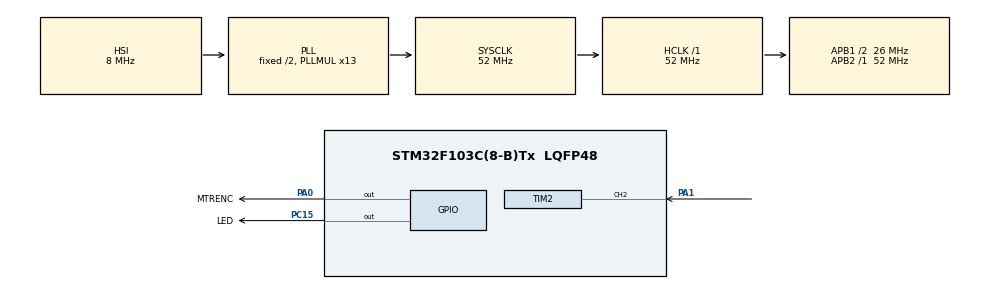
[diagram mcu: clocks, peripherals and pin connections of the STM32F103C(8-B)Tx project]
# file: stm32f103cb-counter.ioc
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Mcu.Family=STM32F1
Mcu.Name=STM32F103C(8-B)Tx
Mcu.Package=LQFP48
NVIC.PriorityGroup=NVIC_PRIORITYGROUP_4
NVIC.TIM1_BRK_IRQn=true\:0\:0\:false\:false\:true\:true\:true
NVIC.TIM1_CC_IRQn=true\:0\:0\:false\:false\:true\:true\:true
NVIC.TIM1_TRG_COM_IRQn=true\:0\:0\:false\:false\:true\:true\:true
NVIC.TIM1_UP_IRQn=true\:0\:0\:false\:false\:true\:true\:true
PA0-WKUP.GPIO_Label=MTRENC
PA0-WKUP.Signal=GPIO_Output
PA1.Signal=S_TIM2_CH2
PA13.Mode=Serial_Wire
PA13.Signal=SYS_JTMS-SWDIO
PA14.Mode=Serial_Wire
PA14.Signal=SYS_JTCK-SWCLK
PC15-OSC32_OUT.GPIO_Label=LED
PC15-OSC32_OUT.Signal=GPIO_Output
ProjectManager.HeapSize=0x200
ProjectManager.StackSize=0x400
ProjectManager.TargetToolchain=STM32CubeIDE
RCC.AHBFreq_Value=52000000
RCC.APB1CLKDivider=RCC_HCLK_DIV2
RCC.APB1Freq_Value=26000000
RCC.APB1TimFreq_Value=52000000
RCC.APB2Freq_Value=52000000
RCC.APB2TimFreq_Value=52000000
RCC.HCLKFreq_Value=52000000
RCC.PLLMUL=RCC_PLL_MUL13
RCC.SYSCLKFreq_VALUE=52000000
RCC.SYSCLKSource=RCC_SYSCLKSOURCE_PLLCLK
RCC.USBFreq_Value=52000000
SH.S_TIM2_CH2.0=TIM2_CH2,TriggerSource_TI2FP2
TIM1.AutoReloadPreload=TIM_AUTORELOAD_PRELOAD_ENABLE
TIM1.Period=10000
TIM1.Prescaler=52
VP_TIM1_VS_ClockSourceINT.Mode=Internal
VP_TIM2_VS_ControllerModeClock.Mode=Clock Mode
board=custom

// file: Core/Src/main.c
/* USER CODE BEGIN Header */
/**
  ******************************************************************************
  * @file           : main.c
  * @brief          : Main program body
  ******************************************************************************
  * @attention
  *
  * <h2><center>&copy; Copyright (c) 2020 STMicroelectronics.
  * All rights reserved.</center></h2>
  *
  * This software component is licensed by ST under BSD 3-Clause license,
  * the "License"; You may not use this file except in compliance with the
  * License. You may obtain a copy of the License at:
  *                        opensource.org/licenses/BSD-3-Clause
  *
  ******************************************************************************
  */
/* USER CODE END Header */
#include "main.h"

TIM_HandleTypeDef htim1;
TIM_HandleTypeDef htim2;

/* USER CODE BEGIN PV */
int tim1Cnt=0;
uint32_t rpmValue=0;
/* USER CODE END PV */

void SystemClock_Config(void);
static void MX_GPIO_Init(void);
static void MX_TIM1_Init(void);
static void MX_TIM2_Init(void);

int main(void)
{

  /* MCU Configuration--------------------------------------------------------*/

  /* Reset of all peripherals, Initializes the Flash interface and the Systick. */
  HAL_Init();

  /* Configure the system clock */
  SystemClock_Config();

  /* Initialize all configured peripherals */
  MX_GPIO_Init();
  MX_TIM1_Init();
  MX_TIM2_Init();
  /* USER CODE BEGIN 2 */
  HAL_GPIO_WritePin(MTRENC_GPIO_Port, MTRENC_Pin, GPIO_PIN_RESET);

  /* USER CODE END 2 */

  /* Infinite loop */
  /* USER CODE BEGIN WHILE */
  while (HAL_TIM_Base_Start_IT(&htim1)!=HAL_OK);
  while (HAL_TIM_Base_Start(&htim2)!=HAL_OK);
  while (1)
  {
    /* USER CODE END WHILE */

  }
}

void SystemClock_Config(void)
{
  RCC_OscInitTypeDef RCC_OscInitStruct = {0};
  RCC_ClkInitTypeDef RCC_ClkInitStruct = {0};

  /** Initializes the RCC Oscillators according to the specified parameters
  * in the RCC_OscInitTypeDef structure.
  */
  RCC_OscInitStruct.OscillatorType = RCC_OSCILLATORTYPE_HSI;
  RCC_OscInitStruct.HSIState = RCC_HSI_ON;
  RCC_OscInitStruct.HSICalibrationValue = RCC_HSICALIBRATION_DEFAULT;
  RCC_OscInitStruct.PLL.PLLState = RCC_PLL_ON;
  RCC_OscInitStruct.PLL.PLLSource = RCC_PLLSOURCE_HSI_DIV2;
  RCC_OscInitStruct.PLL.PLLMUL = RCC_PLL_MUL13;
  if (HAL_RCC_OscConfig(&RCC_OscInitStruct) != HAL_OK)
  {
    Error_Handler();
  }
  /** Initializes the CPU, AHB and APB buses clocks
  */
  RCC_ClkInitStruct.ClockType = RCC_CLOCKTYPE_HCLK|RCC_CLOCKTYPE_SYSCLK
                              |RCC_CLOCKTYPE_PCLK1|RCC_CLOCKTYPE_PCLK2;
  RCC_ClkInitStruct.SYSCLKSource = RCC_SYSCLKSOURCE_PLLCLK;
  RCC_ClkInitStruct.AHBCLKDivider = RCC_SYSCLK_DIV1;
  RCC_ClkInitStruct.APB1CLKDivider = RCC_HCLK_DIV2;
  RCC_ClkInitStruct.APB2CLKDivider = RCC_HCLK_DIV1;

  if (HAL_RCC_ClockConfig(&RCC_ClkInitStruct, FLASH_LATENCY_2) != HAL_OK)
  {
    Error_Handler();
  }
}

static void MX_TIM1_Init(void)
{

  TIM_ClockConfigTypeDef sClockSourceConfig = {0};
  TIM_MasterConfigTypeDef sMasterConfig = {0};

  htim1.Instance = TIM1;
  htim1.Init.Prescaler = 52;
  htim1.Init.CounterMode = TIM_COUNTERMODE_UP;
  htim1.Init.Period = 10000;
  htim1.Init.ClockDivision = TIM_CLOCKDIVISION_DIV1;
  htim1.Init.RepetitionCounter = 0;
  htim1.Init.AutoReloadPreload = TIM_AUTORELOAD_PRELOAD_ENABLE;
  if (HAL_TIM_Base_Init(&htim1) != HAL_OK)
  {
    Error_Handler();
  }
  sClockSourceConfig.ClockSource = TIM_CLOCKSOURCE_INTERNAL;
  if (HAL_TIM_ConfigClockSource(&htim1, &sClockSourceConfig) != HAL_OK)
  {
    Error_Handler();
  }
  sMasterConfig.MasterOutputTrigger = TIM_TRGO_RESET;
  sMasterConfig.MasterSlaveMode = TIM_MASTERSLAVEMODE_DISABLE;
  if (HAL_TIMEx_MasterConfigSynchronization(&htim1, &sMasterConfig) != HAL_OK)
  {
    Error_Handler();
  }

}

static void MX_TIM2_Init(void)
{

  TIM_SlaveConfigTypeDef sSlaveConfig = {0};
  TIM_MasterConfigTypeDef sMasterConfig = {0};

  htim2.Instance = TIM2;
  htim2.Init.Prescaler = 0;
  htim2.Init.CounterMode = TIM_COUNTERMODE_UP;
  htim2.Init.Period = 65535;
  htim2.Init.ClockDivision = TIM_CLOCKDIVISION_DIV1;
  htim2.Init.AutoReloadPreload = TIM_AUTORELOAD_PRELOAD_DISABLE;
  if (HAL_TIM_Base_Init(&htim2) != HAL_OK)
  {
    Error_Handler();
  }
  sSlaveConfig.SlaveMode = TIM_SLAVEMODE_EXTERNAL1;
  sSlaveConfig.InputTrigger = TIM_TS_TI2FP2;
  sSlaveConfig.TriggerPolarity = TIM_TRIGGERPOLARITY_RISING;
  sSlaveConfig.TriggerFilter = 0;
  if (HAL_TIM_SlaveConfigSynchro(&htim2, &sSlaveConfig) != HAL_OK)
  {
    Error_Handler();
  }
  sMasterConfig.MasterOutputTrigger = TIM_TRGO_RESET;
  sMasterConfig.MasterSlaveMode = TIM_MASTERSLAVEMODE_DISABLE;
  if (HAL_TIMEx_MasterConfigSynchronization(&htim2, &sMasterConfig) != HAL_OK)
  {
    Error_Handler();
  }

}

static void MX_GPIO_Init(void)
{
  GPIO_InitTypeDef GPIO_InitStruct = {0};

  /* GPIO Ports Clock Enable */
  __HAL_RCC_GPIOC_CLK_ENABLE();
  __HAL_RCC_GPIOA_CLK_ENABLE();

  /*Configure GPIO pin Output Level */
  HAL_GPIO_WritePin(LED_GPIO_Port, LED_Pin, GPIO_PIN_RESET);

  /*Configure GPIO pin Output Level */
  HAL_GPIO_WritePin(MTRENC_GPIO_Port, MTRENC_Pin, GPIO_PIN_RESET);

  /*Configure GPIO pin : LED_Pin */
  GPIO_InitStruct.Pin = LED_Pin;
  GPIO_InitStruct.Mode = GPIO_MODE_OUTPUT_PP;
  GPIO_InitStruct.Pull = GPIO_NOPULL;
  GPIO_InitStruct.Speed = GPIO_SPEED_FREQ_LOW;
  HAL_GPIO_Init(LED_GPIO_Port, &GPIO_InitStruct);

  /*Configure GPIO pin : MTRENC_Pin */
  GPIO_InitStruct.Pin = MTRENC_Pin;
  GPIO_InitStruct.Mode = GPIO_MODE_OUTPUT_PP;
  GPIO_InitStruct.Pull = GPIO_NOPULL;
  GPIO_InitStruct.Speed = GPIO_SPEED_FREQ_LOW;
  HAL_GPIO_Init(MTRENC_GPIO_Port, &GPIO_InitStruct);

}

/* USER CODE BEGIN 4 */
void HAL_TIM_PeriodElapsedCallback(TIM_HandleTypeDef *htim)
{

	uint32_t count;
	__NOP();
   if (htim->Instance==TIM1)
	  {
	   if (tim1Cnt==100)
	   {
		   count = __HAL_TIM_GET_COUNTER(&htim2);
		   rpmValue = count * 60;
		   HAL_GPIO_TogglePin(LED_GPIO_Port, LED_Pin);
		   tim1Cnt=0;
		   HAL_GPIO_WritePin(MTRENC_GPIO_Port, MTRENC_Pin, GPIO_PIN_RESET);
		   __HAL_TIM_SET_COUNTER(&htim2,0);
	   }
	   else
	   {
		   HAL_GPIO_TogglePin(MTRENC_GPIO_Port, MTRENC_Pin);
		   tim1Cnt++;
	   }
	   HAL_TIM_Base_Start_IT(&htim1);
	  //do something here
	  }

  /* Prevent unused argument(s) compilation warning */
//  UNUSED(htim);

  /* NOTE : This function should not be modified, when the callback is needed,
            the HAL_TIM_PeriodElapsedCallback could be implemented in the user file
   */
}
/* USER CODE END 4 */

void Error_Handler(void)
{
}

/************************ (C) COPYRIGHT STMicroelectronics *****END OF FILE****/
